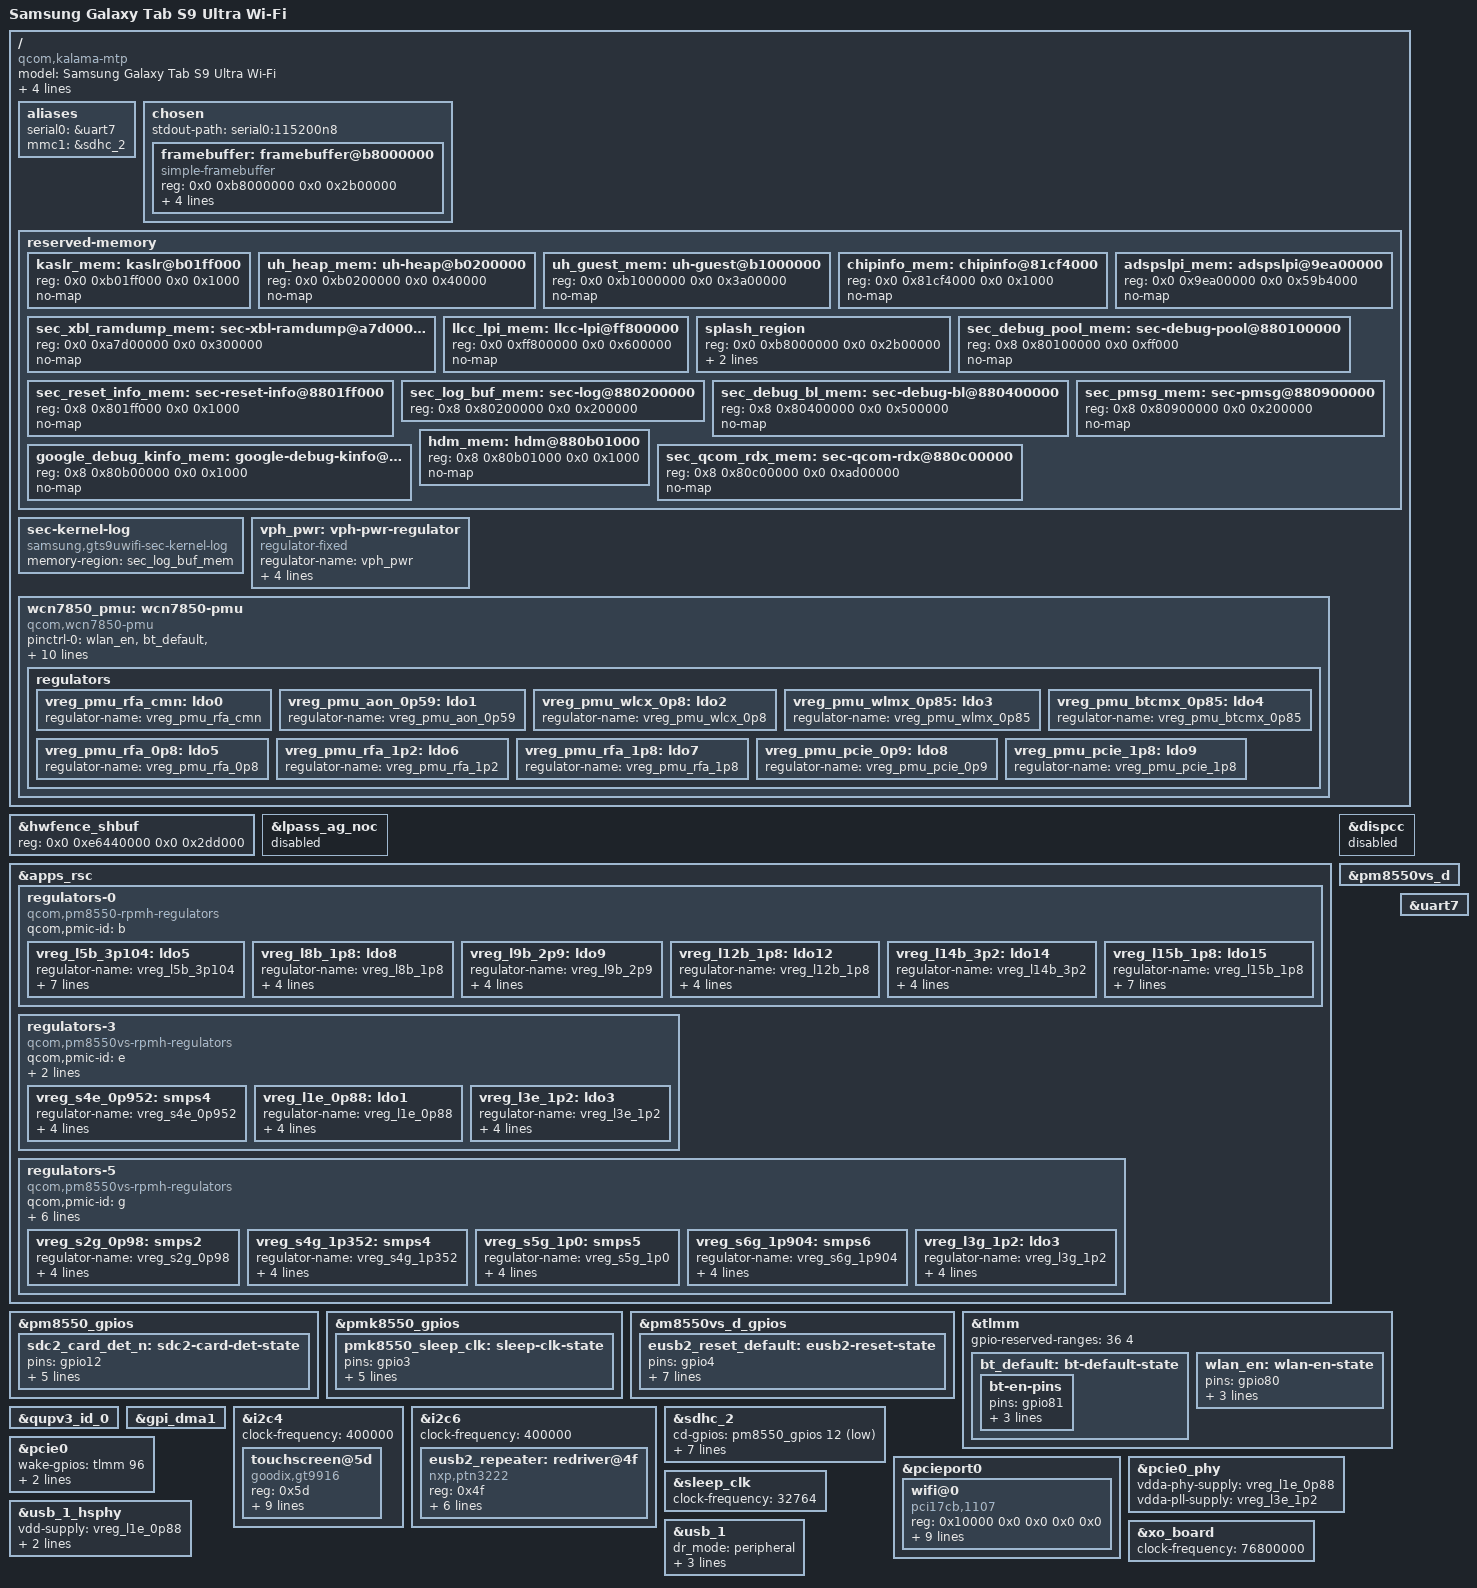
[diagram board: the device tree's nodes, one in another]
// SPDX-License-Identifier: BSD-3-Clause
/*
 * Initial mainline device tree for the Samsung Galaxy Tab S9 Ultra Wi-Fi
 * (SM-X910, gts9uwifi).
 *
 * Only hardware evidenced by the live downstream tree is enabled here.
 * Native display support remains disabled; Samsung ABL's preserved splash
 * framebuffer is used for the first visual milestone.
 */

/dts-v1/;

#include <dt-bindings/gpio/gpio.h>
#include <dt-bindings/interrupt-controller/irq.h>
#include <dt-bindings/pinctrl/qcom,pmic-gpio.h>
#include <dt-bindings/regulator/qcom,rpmh-regulator.h>
#include "sm8550.dtsi"
#include "pm8550.dtsi"
#include "pm8550vs.dtsi"
#include "pmk8550.dtsi"

/* Samsung's ADSP/SLPI carveout is larger than the SM8550 reference value. */
/delete-node/ &adspslpi_mem;

/ {
	model = "Samsung Galaxy Tab S9 Ultra Wi-Fi";
	/*
	 * The first three strings and the legacy IDs are consumed by Samsung ABL
	 * when it selects the base DTB.  Keep the upstream compatibles as well so
	 * Linux still identifies the actual board and SoC normally.
	 */
	compatible = "qcom,kalama-mtp", "qcom,kalama", "qcom,mtp",
		     "samsung,gts9uwifi", "qcom,sm8550";
	qcom,msm-id = <0x218 0x20000 0x207 0x20000
		       0x207 0x10000 0x218 0x10000>;
	qcom,board-id = <0x10008 0x03>;
	chassis-type = "tablet";

	aliases {
		serial0 = &uart7;
		mmc1 = &sdhc_2;
	};

	chosen {
		#address-cells = <2>;
		#size-cells = <2>;
		ranges;
		stdout-path = "serial0:115200n8";

		framebuffer: framebuffer@b8000000 {
			compatible = "simple-framebuffer";
			reg = <0x0 0xb8000000 0x0 0x2b00000>;
			width = <2960>;
			height = <1848>;
			stride = <(2960 * 4)>;
			format = "a8r8g8b8";
		};
	};

	reserved-memory {
		/*
		 * Samsung ABL patches the /memory ranges but, without the stock
		 * overlay, does not add the board-only protected carveouts below.
		 * Keep them out of the buddy allocator: touching one of these ranges
		 * can make the secure firmware reset the SoC with a fatal NoC error.
		 */
		kaslr_mem: kaslr@b01ff000 {
			reg = <0x0 0xb01ff000 0x0 0x1000>;
			no-map;
		};

		uh_heap_mem: uh-heap@b0200000 {
			reg = <0x0 0xb0200000 0x0 0x40000>;
			no-map;
		};

		uh_guest_mem: uh-guest@b1000000 {
			reg = <0x0 0xb1000000 0x0 0x3a00000>;
			no-map;
		};

		chipinfo_mem: chipinfo@81cf4000 {
			reg = <0x0 0x81cf4000 0x0 0x1000>;
			no-map;
		};

		sec_xbl_ramdump_mem: sec-xbl-ramdump@a7d00000 {
			reg = <0x0 0xa7d00000 0x0 0x300000>;
			no-map;
		};

		adspslpi_mem: adspslpi@9ea00000 {
			reg = <0x0 0x9ea00000 0x0 0x59b4000>;
			no-map;
		};

		llcc_lpi_mem: llcc-lpi@ff800000 {
			reg = <0x0 0xff800000 0x0 0x600000>;
			no-map;
		};

		/* X910 ABL expects this exact downstream node name and label. */
		splash_region {
			reg = <0x0 0xb8000000 0x0 0x2b00000>;
			label = "cont_splash_region";
			no-map;
		};

		sec_debug_pool_mem: sec-debug-pool@880100000 {
			reg = <0x8 0x80100000 0x0 0xff000>;
			no-map;
		};

		sec_reset_info_mem: sec-reset-info@8801ff000 {
			reg = <0x8 0x801ff000 0x0 0x1000>;
			no-map;
		};

		/* Shared with Samsung bootloader and recovery for /proc/last_kmsg. */
		sec_log_buf_mem: sec-log@880200000 {
			reg = <0x8 0x80200000 0x0 0x200000>;
		};

		sec_debug_bl_mem: sec-debug-bl@880400000 {
			reg = <0x8 0x80400000 0x0 0x500000>;
			no-map;
		};

		sec_pmsg_mem: sec-pmsg@880900000 {
			reg = <0x8 0x80900000 0x0 0x200000>;
			no-map;
		};

		google_debug_kinfo_mem: google-debug-kinfo@880b00000 {
			reg = <0x8 0x80b00000 0x0 0x1000>;
			no-map;
		};

		hdm_mem: hdm@880b01000 {
			reg = <0x8 0x80b01000 0x0 0x1000>;
			no-map;
		};

		sec_qcom_rdx_mem: sec-qcom-rdx@880c00000 {
			reg = <0x8 0x80c00000 0x0 0xad00000>;
			no-map;
		};
	};

	sec-kernel-log {
		compatible = "samsung,gts9uwifi-sec-kernel-log";
		memory-region = <&sec_log_buf_mem>;
	};

	/* Mainline WCN7850 power sequencer input, as on the SM8550 QRD. */
	vph_pwr: vph-pwr-regulator {
		compatible = "regulator-fixed";
		regulator-name = "vph_pwr";
		regulator-min-microvolt = <3700000>;
		regulator-max-microvolt = <3700000>;
		regulator-always-on;
		regulator-boot-on;
	};

	wcn7850_pmu: wcn7850-pmu {
		compatible = "qcom,wcn7850-pmu";
		pinctrl-names = "default";
		pinctrl-0 = <&wlan_en>, <&bt_default>, <&pmk8550_sleep_clk>;

		/* These are GPIO80/81 in the live X910 downstream tree. */
		wlan-enable-gpios = <&tlmm 80 GPIO_ACTIVE_HIGH>;
		bt-enable-gpios = <&tlmm 81 GPIO_ACTIVE_HIGH>;

		vdd-supply = <&vreg_s5g_1p0>;
		vddio-supply = <&vreg_l15b_1p8>;
		/* Stock Kiwi v2 votes PM8550VS-G L3 through its WCN PDC map. */
		vddio1p2-supply = <&vreg_l3g_1p2>;
		vddaon-supply = <&vreg_s2g_0p98>;
		vdddig-supply = <&vreg_s4e_0p952>;
		vddrfa1p2-supply = <&vreg_s4g_1p352>;
		vddrfa1p8-supply = <&vreg_s6g_1p904>;

		regulators {
			vreg_pmu_rfa_cmn: ldo0 {
				regulator-name = "vreg_pmu_rfa_cmn";
			};

			vreg_pmu_aon_0p59: ldo1 {
				regulator-name = "vreg_pmu_aon_0p59";
			};

			vreg_pmu_wlcx_0p8: ldo2 {
				regulator-name = "vreg_pmu_wlcx_0p8";
			};

			vreg_pmu_wlmx_0p85: ldo3 {
				regulator-name = "vreg_pmu_wlmx_0p85";
			};

			vreg_pmu_btcmx_0p85: ldo4 {
				regulator-name = "vreg_pmu_btcmx_0p85";
			};

			vreg_pmu_rfa_0p8: ldo5 {
				regulator-name = "vreg_pmu_rfa_0p8";
			};

			vreg_pmu_rfa_1p2: ldo6 {
				regulator-name = "vreg_pmu_rfa_1p2";
			};

			vreg_pmu_rfa_1p8: ldo7 {
				regulator-name = "vreg_pmu_rfa_1p8";
			};

			vreg_pmu_pcie_0p9: ldo8 {
				regulator-name = "vreg_pmu_pcie_0p9";
			};

			vreg_pmu_pcie_1p8: ldo9 {
				regulator-name = "vreg_pmu_pcie_1p8";
			};
		};
	};
};

/* The X910 firmware reserves a slightly larger HW-fence window than MTP. */
&hwfence_shbuf {
	reg = <0x0 0xe6440000 0x0 0x2dd000>;
};

/*
 * The v0.5 video ends after the two preceding LPASS NOC providers probe and
 * before this provider can return.  Audio is out of scope for milestone 1;
 * keep the unsafe access quiescent until its board-specific power sequence is
 * understood.
 */
&lpass_ag_noc {
	status = "disabled";
};

&apps_rsc {
	/* PM8550B: only the two external-SD rails needed for milestone 1. */
	regulators-0 {
		compatible = "qcom,pm8550-rpmh-regulators";
		qcom,pmic-id = "b";

		/* NXP PTN3222 eUSB2 3.1 V rail, exact X910 stock voltage. */
		vreg_l5b_3p104: ldo5 {
			regulator-name = "vreg_l5b_3p104";
			regulator-min-microvolt = <3104000>;
			regulator-max-microvolt = <3104000>;
			regulator-initial-mode = <RPMH_REGULATOR_MODE_HPM>;
			regulator-allow-set-load;
			regulator-allowed-modes = <RPMH_REGULATOR_MODE_LPM
						   RPMH_REGULATOR_MODE_HPM>;
		};

		vreg_l8b_1p8: ldo8 {
			regulator-name = "vreg_l8b_1p8";
			regulator-min-microvolt = <1800000>;
			regulator-max-microvolt = <3000000>;
			regulator-initial-mode = <RPMH_REGULATOR_MODE_HPM>;
		};

		vreg_l9b_2p9: ldo9 {
			regulator-name = "vreg_l9b_2p9";
			regulator-min-microvolt = <2960000>;
			regulator-max-microvolt = <3000000>;
			regulator-initial-mode = <RPMH_REGULATOR_MODE_HPM>;
		};

		vreg_l12b_1p8: ldo12 {
			regulator-name = "vreg_l12b_1p8";
			regulator-min-microvolt = <1800000>;
			regulator-max-microvolt = <1800000>;
			regulator-initial-mode = <RPMH_REGULATOR_MODE_HPM>;
		};

		vreg_l14b_3p2: ldo14 {
			regulator-name = "vreg_l14b_3p2";
			regulator-min-microvolt = <3200000>;
			regulator-max-microvolt = <3200000>;
			regulator-initial-mode = <RPMH_REGULATOR_MODE_HPM>;
		};

		/* NXP PTN3222 eUSB2 1.8 V rail. */
		vreg_l15b_1p8: ldo15 {
			regulator-name = "vreg_l15b_1p8";
			regulator-min-microvolt = <1800000>;
			regulator-max-microvolt = <1800000>;
			regulator-initial-mode = <RPMH_REGULATOR_MODE_HPM>;
			regulator-allow-set-load;
			regulator-allowed-modes = <RPMH_REGULATOR_MODE_LPM
						   RPMH_REGULATOR_MODE_HPM>;
		};
	};

	/* PM8550VS-E: rails consumed by the primary USB2 PHY. */
	regulators-3 {
		compatible = "qcom,pm8550vs-rpmh-regulators";
		qcom,pmic-id = "e";
		vdd-s4-supply = <&vph_pwr>;
		vdd-s5-supply = <&vph_pwr>;

		vreg_s4e_0p952: smps4 {
			regulator-name = "vreg_s4e_0p952";
			/* Stock asks 0.950 V; FTSMPS525 rounds up in 4 mV steps. */
			regulator-min-microvolt = <952000>;
			regulator-max-microvolt = <952000>;
			regulator-initial-mode = <RPMH_REGULATOR_MODE_HPM>;
		};

		vreg_l1e_0p88: ldo1 {
			regulator-name = "vreg_l1e_0p88";
			regulator-min-microvolt = <880000>;
			regulator-max-microvolt = <880000>;
			regulator-initial-mode = <RPMH_REGULATOR_MODE_HPM>;
		};

		vreg_l3e_1p2: ldo3 {
			regulator-name = "vreg_l3e_1p2";
			regulator-min-microvolt = <1200000>;
			regulator-max-microvolt = <1200000>;
			regulator-initial-mode = <RPMH_REGULATOR_MODE_HPM>;
		};
	};

	/* PM8550VS-G supplies the discrete WCN7850/Kiwi v2 radio PMU. */
	regulators-5 {
		compatible = "qcom,pm8550vs-rpmh-regulators";
		qcom,pmic-id = "g";
		vdd-s1-supply = <&vph_pwr>;
		vdd-s2-supply = <&vph_pwr>;
		vdd-s3-supply = <&vph_pwr>;
		vdd-s4-supply = <&vph_pwr>;
		vdd-s5-supply = <&vph_pwr>;
		vdd-s6-supply = <&vph_pwr>;

		vreg_s2g_0p98: smps2 {
			regulator-name = "vreg_s2g_0p98";
			/* X910 chip_cfg@1 votes exactly 0.980 V for WLAN_AON. */
			regulator-min-microvolt = <980000>;
			regulator-max-microvolt = <980000>;
			regulator-initial-mode = <RPMH_REGULATOR_MODE_HPM>;
		};

		vreg_s4g_1p352: smps4 {
			regulator-name = "vreg_s4g_1p352";
			/* Stock asks 1.350 V; FTSMPS525 rounds up in 4 mV steps. */
			regulator-min-microvolt = <1352000>;
			regulator-max-microvolt = <1352000>;
			regulator-initial-mode = <RPMH_REGULATOR_MODE_HPM>;
		};

		vreg_s5g_1p0: smps5 {
			regulator-name = "vreg_s5g_1p0";
			/* X910 chip_cfg@1 votes exactly 1.000 V for WLAN. */
			regulator-min-microvolt = <1000000>;
			regulator-max-microvolt = <1000000>;
			regulator-initial-mode = <RPMH_REGULATOR_MODE_HPM>;
		};

		vreg_s6g_1p904: smps6 {
			regulator-name = "vreg_s6g_1p904";
			/* Stock asks 1.900 V; FTSMPS525 rounds up in 8 mV steps. */
			regulator-min-microvolt = <1904000>;
			regulator-max-microvolt = <1904000>;
			regulator-initial-mode = <RPMH_REGULATOR_MODE_HPM>;
		};

		/*
		 * Do not add vdd-l3-supply here.  Mainline SM8550 boards expose
		 * PM8550VS-G LDO3 directly, and the experimental S4G parent used in
		 * v0.20 created a fixed dependency cycle with this provider.
		 */
		vreg_l3g_1p2: ldo3 {
			regulator-name = "vreg_l3g_1p2";
			regulator-min-microvolt = <1200000>;
			regulator-max-microvolt = <1200000>;
			regulator-initial-mode = <RPMH_REGULATOR_MODE_HPM>;
		};
	};
};

&dispcc {
	status = "disabled";
};

&pm8550_gpios {
	sdc2_card_det_n: sdc2-card-det-state {
		pins = "gpio12";
		function = "normal";
		input-enable;
		output-disable;
		bias-pull-up;
		power-source = <1>; /* 1.8 V */
	};
};

&pmk8550_gpios {
	pmk8550_sleep_clk: sleep-clk-state {
		pins = "gpio3";
		function = "func1";
		input-disable;
		output-enable;
		bias-disable;
		power-source = <0>;
	};
};

/* Stock X910 connects the NXP repeater reset to PM8550VS-D GPIO4. */
&pm8550vs_d {
	status = "okay";
};

&pm8550vs_d_gpios {
	eusb2_reset_default: eusb2-reset-state {
		pins = "gpio4";
		function = "normal";
		power-source = <1>;
		input-enable;
		output-enable;
		drive-push-pull;
		qcom,drive-strength = <PMIC_GPIO_STRENGTH_MED>;
		bias-disable;
	};
};

&tlmm {
	/*
	 * The Samsung board overlay marks GPIO36..39 as secure/reserved.  Use
	 * the generic binding understood by mainline gpiolib so registration
	 * does not access the TrustZone-owned TLMM registers.
	 */
	gpio-reserved-ranges = <36 4>;

	bt_default: bt-default-state {
		bt-en-pins {
			pins = "gpio81";
			function = "gpio";
			drive-strength = <16>;
			bias-disable;
		};
	};

	wlan_en: wlan-en-state {
		pins = "gpio80";
		function = "gpio";
		drive-strength = <16>;
		bias-pull-up;
	};
};

&qupv3_id_0 {
	status = "okay";
};

/* I2C4 (touch) and I2C6 (PTN3222) are GPI-only on SM8550. */
&gpi_dma1 {
	status = "okay";
};

&i2c4 {
	clock-frequency = <400000>;
	status = "okay";

	touchscreen@5d {
		compatible = "goodix,gt9916";
		reg = <0x5d>;
		interrupts-extended = <&tlmm 25 IRQ_TYPE_LEVEL_LOW>;
		reset-gpios = <&tlmm 24 GPIO_ACTIVE_LOW>;
		avdd-supply = <&vreg_l14b_3p2>;
		vddio-supply = <&vreg_l12b_1p8>;
		touchscreen-size-x = <1848>;
		touchscreen-size-y = <2960>;
		touchscreen-inverted-x;
		touchscreen-swapped-x-y;
	};
};

&i2c6 {
	clock-frequency = <400000>;
	status = "okay";

	eusb2_repeater: redriver@4f {
		compatible = "nxp,ptn3222";
		reg = <0x4f>;
		#phy-cells = <0>;

		vdd3v3-supply = <&vreg_l5b_3p104>;
		vdd1v8-supply = <&vreg_l15b_1p8>;
		reset-gpios = <&pm8550vs_d_gpios 4 GPIO_ACTIVE_LOW>;
		qcom,param-override-seq = <0x20 0x06 0x21 0x07
					   0x63 0x08 0x01 0x0a>;

		pinctrl-names = "default";
		pinctrl-0 = <&eusb2_reset_default>;
	};
};

&uart7 {
	status = "okay";
};

&sdhc_2 {
	cd-gpios = <&pm8550_gpios 12 GPIO_ACTIVE_LOW>;
	pinctrl-names = "default", "sleep";
	pinctrl-0 = <&sdc2_default &sdc2_card_det_n>;
	pinctrl-1 = <&sdc2_sleep &sdc2_card_det_n>;
	vmmc-supply = <&vreg_l9b_2p9>;
	vqmmc-supply = <&vreg_l8b_1p8>;
	bus-width = <4>;
	no-sdio;
	no-mmc;
	status = "okay";
};

/* X910 downstream uses PCIe0 and GPIO94/96 for the Kiwi v2 WLAN endpoint. */
&pcie0 {
	wake-gpios = <&tlmm 96 GPIO_ACTIVE_HIGH>;
	perst-gpios = <&tlmm 94 GPIO_ACTIVE_LOW>;
	pinctrl-0 = <&pcie0_default_state>;
	pinctrl-names = "default";
	status = "okay";
};

&pcieport0 {
	wifi@0 {
		compatible = "pci17cb,1107";
		reg = <0x10000 0x0 0x0 0x0 0x0>;
		vddrfacmn-supply = <&vreg_pmu_rfa_cmn>;
		vddaon-supply = <&vreg_pmu_aon_0p59>;
		vddwlcx-supply = <&vreg_pmu_wlcx_0p8>;
		vddwlmx-supply = <&vreg_pmu_wlmx_0p85>;
		vddrfa0p8-supply = <&vreg_pmu_rfa_0p8>;
		vddrfa1p2-supply = <&vreg_pmu_rfa_1p2>;
		vddrfa1p8-supply = <&vreg_pmu_rfa_1p8>;
		vddpcie0p9-supply = <&vreg_pmu_pcie_0p9>;
		vddpcie1p8-supply = <&vreg_pmu_pcie_1p8>;
	};
};

&pcie0_phy {
	vdda-phy-supply = <&vreg_l1e_0p88>;
	vdda-pll-supply = <&vreg_l3e_1p2>;
	status = "okay";
};

&sleep_clk {
	clock-frequency = <32764>;
};

/* X910 uses a PTN3222-compatible NXP eUSB2 repeater on I2C6. */
&usb_1_hsphy {
	vdd-supply = <&vreg_l1e_0p88>;
	vdda12-supply = <&vreg_l3e_1p2>;
	phys = <&eusb2_repeater>;
	status = "okay";
};

&usb_1 {
	/delete-property/ usb-role-switch;
	/delete-property/ phys;
	/delete-property/ phy-names;
	dr_mode = "peripheral";
	maximum-speed = "high-speed";
	qcom,select-utmi-as-pipe-clk;
	phys = <&usb_1_hsphy>;
	phy-names = "usb2-phy";
	status = "okay";
};

&xo_board {
	clock-frequency = <76800000>;
};
